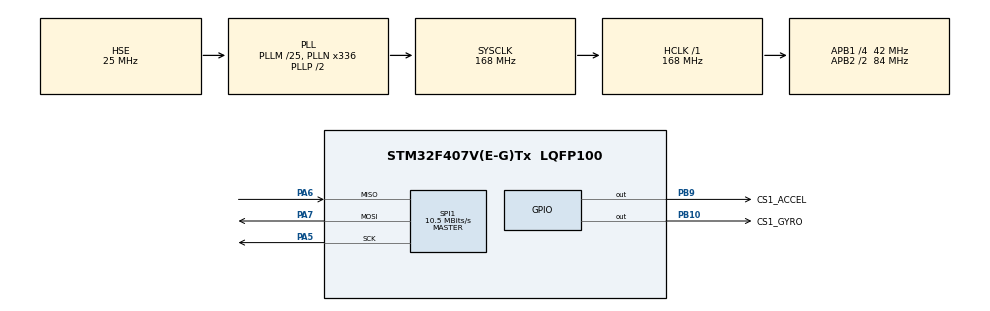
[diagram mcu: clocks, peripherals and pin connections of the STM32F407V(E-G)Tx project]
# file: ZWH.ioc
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FREERTOS.Tasks01=BMI088,0,128,bmi088,Default,NULL,Dynamic,NULL,NULL
Mcu.Family=STM32F4
Mcu.Name=STM32F407V(E-G)Tx
Mcu.Package=LQFP100
NVIC.PriorityGroup=NVIC_PRIORITYGROUP_4
NVIC.TIM6_DAC_IRQn=true\:15\:0\:false\:false\:true\:false\:false\:true\:true
NVIC.TimeBase=TIM6_DAC_IRQn
NVIC.TimeBaseIP=TIM6
PA13.Mode=Serial_Wire
PA13.Signal=SYS_JTMS-SWDIO
PA14.Mode=Serial_Wire
PA14.Signal=SYS_JTCK-SWCLK
PA5.Mode=Full_Duplex_Master
PA5.Signal=SPI1_SCK
PA6.Mode=Full_Duplex_Master
PA6.Signal=SPI1_MISO
PA7.Mode=Full_Duplex_Master
PA7.Signal=SPI1_MOSI
PB10.GPIO_Label=CS1_GYRO
PB10.GPIO_PuPd=GPIO_PULLUP
PB10.GPIO_Speed=GPIO_SPEED_FREQ_HIGH
PB10.PinState=GPIO_PIN_SET
PB10.Signal=GPIO_Output
PB9.GPIO_Label=CS1_ACCEL
PB9.GPIO_PuPd=GPIO_PULLUP
PB9.GPIO_Speed=GPIO_SPEED_FREQ_HIGH
PB9.PinState=GPIO_PIN_SET
PB9.Signal=GPIO_Output
PC14-OSC32_IN.Mode=LSE-External-Oscillator
PC14-OSC32_IN.Signal=RCC_OSC32_IN
PC15-OSC32_OUT.Mode=LSE-External-Oscillator
PC15-OSC32_OUT.Signal=RCC_OSC32_OUT
PH0-OSC_IN.Mode=HSE-External-Oscillator
PH0-OSC_IN.Signal=RCC_OSC_IN
PH1-OSC_OUT.Mode=HSE-External-Oscillator
PH1-OSC_OUT.Signal=RCC_OSC_OUT
ProjectManager.HeapSize=0x2000
ProjectManager.StackSize=0x2000
ProjectManager.TargetToolchain=MDK-ARM V5.32
RCC.48MHZClocksFreq_Value=84000000
RCC.AHBFreq_Value=168000000
RCC.APB1CLKDivider=RCC_HCLK_DIV4
RCC.APB1Freq_Value=42000000
RCC.APB1TimFreq_Value=84000000
RCC.APB2CLKDivider=RCC_HCLK_DIV2
RCC.APB2Freq_Value=84000000
RCC.APB2TimFreq_Value=168000000
RCC.CortexFreq_Value=168000000
RCC.HCLKFreq_Value=168000000
RCC.HSE_VALUE=25000000
RCC.HSI_VALUE=16000000
RCC.PLLM=25
RCC.PLLN=336
RCC.PLLSourceVirtual=RCC_PLLSOURCE_HSE
RCC.SYSCLKFreq_VALUE=168000000
RCC.SYSCLKSource=RCC_SYSCLKSOURCE_PLLCLK
RCC.VCOOutputFreq_Value=336000000
SPI1.BaudRatePrescaler=SPI_BAUDRATEPRESCALER_8
SPI1.CLKPhase=SPI_PHASE_2EDGE
SPI1.CLKPolarity=SPI_POLARITY_HIGH
SPI1.CalculateBaudRate=10.5 MBits/s
SPI1.Direction=SPI_DIRECTION_2LINES
SPI1.Mode=SPI_MODE_MASTER
SPI1.VirtualType=VM_MASTER
STMicroelectronics.X-CUBE-ALGOBUILD.1.3.0.LibraryCcDSPOoLibraryJjDSPOoLibrary=true
VP_FREERTOS_VS_CMSIS_V1.Mode=CMSIS_V1
VP_STMicroelectronics.X-CUBE-ALGOBUILD_VS_DSPOoLibraryJjLibrary_1.3.0_1.3.0.Mode=DSPOoLibraryJjLibrary
VP_SYS_VS_tim6.Mode=TIM6
board=custom

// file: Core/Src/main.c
/* USER CODE BEGIN Header */
/**
  ******************************************************************************
  * @file           : main.c
  * @brief          : Main program body
  ******************************************************************************
  * @attention
  *
  * Copyright (c) 2024 STMicroelectronics.
  * All rights reserved.
  *
  * This software is licensed under terms that can be found in the LICENSE file
  * in the root directory of this software component.
  * If no LICENSE file comes with this software, it is provided AS-IS.
  *
  ******************************************************************************
  */
/* USER CODE END Header */
#include "main.h"
#include "cmsis_os.h"
#include "spi.h"
#include "gpio.h"

/* USER CODE BEGIN Includes */

#include "bsp_dwt.h"
#include "BMI088driver.h"
/* USER CODE END Includes */

void SystemClock_Config(void);
void MX_FREERTOS_Init(void);

int main(void)
{

  /* MCU Configuration--------------------------------------------------------*/

  /* Reset of all peripherals, Initializes the Flash interface and the Systick. */
  HAL_Init();

  /* Configure the system clock */
  SystemClock_Config();

  /* Initialize all configured peripherals */
  MX_GPIO_Init();
  MX_SPI1_Init();
  /* USER CODE BEGIN 2 */
  DWT_Init(168);
	  while(BMI088_init(&hspi1, 1)!=BMI088_NO_ERROR);
  /* USER CODE END 2 */

  /* Call init function for freertos objects (in cmsis_os2.c) */
  MX_FREERTOS_Init();

  /* Start scheduler */
  osKernelStart();

  /* We should never get here as control is now taken by the scheduler */

  /* Infinite loop */
  while (1)
  {

  }
}

void SystemClock_Config(void)
{
  RCC_OscInitTypeDef RCC_OscInitStruct = {0};
  RCC_ClkInitTypeDef RCC_ClkInitStruct = {0};

  /** Configure the main internal regulator output voltage
  */
  __HAL_RCC_PWR_CLK_ENABLE();
  __HAL_PWR_VOLTAGESCALING_CONFIG(PWR_REGULATOR_VOLTAGE_SCALE1);

  /** Initializes the RCC Oscillators according to the specified parameters
  * in the RCC_OscInitTypeDef structure.
  */
  RCC_OscInitStruct.OscillatorType = RCC_OSCILLATORTYPE_HSE;
  RCC_OscInitStruct.HSEState = RCC_HSE_ON;
  RCC_OscInitStruct.PLL.PLLState = RCC_PLL_ON;
  RCC_OscInitStruct.PLL.PLLSource = RCC_PLLSOURCE_HSE;
  RCC_OscInitStruct.PLL.PLLM = 25;
  RCC_OscInitStruct.PLL.PLLN = 336;
  RCC_OscInitStruct.PLL.PLLP = RCC_PLLP_DIV2;
  RCC_OscInitStruct.PLL.PLLQ = 4;
  if (HAL_RCC_OscConfig(&RCC_OscInitStruct) != HAL_OK)
  {
    Error_Handler();
  }

  /** Initializes the CPU, AHB and APB buses clocks
  */
  RCC_ClkInitStruct.ClockType = RCC_CLOCKTYPE_HCLK|RCC_CLOCKTYPE_SYSCLK
                              |RCC_CLOCKTYPE_PCLK1|RCC_CLOCKTYPE_PCLK2;
  RCC_ClkInitStruct.SYSCLKSource = RCC_SYSCLKSOURCE_PLLCLK;
  RCC_ClkInitStruct.AHBCLKDivider = RCC_SYSCLK_DIV1;
  RCC_ClkInitStruct.APB1CLKDivider = RCC_HCLK_DIV4;
  RCC_ClkInitStruct.APB2CLKDivider = RCC_HCLK_DIV2;

  if (HAL_RCC_ClockConfig(&RCC_ClkInitStruct, FLASH_LATENCY_5) != HAL_OK)
  {
    Error_Handler();
  }
}

void HAL_TIM_PeriodElapsedCallback(TIM_HandleTypeDef *htim)
{
  if (htim->Instance == TIM6) {
    HAL_IncTick();
  }
}

void Error_Handler(void)
{
  __disable_irq();
  while (1)
  {
  }
}

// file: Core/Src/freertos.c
/* USER CODE BEGIN Header */
/**
  ******************************************************************************
  * File Name          : freertos.c
  * Description        : Code for freertos applications
  ******************************************************************************
  * @attention
  *
  * Copyright (c) 2024 STMicroelectronics.
  * All rights reserved.
  *
  * This software is licensed under terms that can be found in the LICENSE file
  * in the root directory of this software component.
  * If no LICENSE file comes with this software, it is provided AS-IS.
  *
  ******************************************************************************
  */
/* USER CODE END Header */

#include "FreeRTOS.h"
#include "task.h"
#include "main.h"
#include "cmsis_os.h"

/* USER CODE BEGIN Includes */
#include "ins_task.h"
/* USER CODE END Includes */

osThreadId BMI088Handle;

void bmi088(void const * argument);

void MX_FREERTOS_Init(void); /* (MISRA C 2004 rule 8.1) */

/* GetIdleTaskMemory prototype (linked to static allocation support) */
void vApplicationGetIdleTaskMemory( StaticTask_t **ppxIdleTaskTCBBuffer, StackType_t **ppxIdleTaskStackBuffer, uint32_t *pulIdleTaskStackSize );

/* USER CODE BEGIN GET_IDLE_TASK_MEMORY */
static StaticTask_t xIdleTaskTCBBuffer;
static StackType_t xIdleStack[configMINIMAL_STACK_SIZE];

void vApplicationGetIdleTaskMemory( StaticTask_t **ppxIdleTaskTCBBuffer, StackType_t **ppxIdleTaskStackBuffer, uint32_t *pulIdleTaskStackSize )
{
  *ppxIdleTaskTCBBuffer = &xIdleTaskTCBBuffer;
  *ppxIdleTaskStackBuffer = &xIdleStack[0];
  *pulIdleTaskStackSize = configMINIMAL_STACK_SIZE;
  /* place for user code */
}
/* USER CODE END GET_IDLE_TASK_MEMORY */

void MX_FREERTOS_Init(void) {

  /* Create the thread(s) */
  /* definition and creation of BMI088 */
  osThreadDef(BMI088, bmi088, osPriorityNormal, 0, 128);
  BMI088Handle = osThreadCreate(osThread(BMI088), NULL);

}

void bmi088(void const * argument)
{
  /* USER CODE BEGIN bmi088 */
	INS_Init();
  /* Infinite loop */
  for(;;)
  {
		INS_Task();
    osDelay(1);
  }
  /* USER CODE END bmi088 */
}
